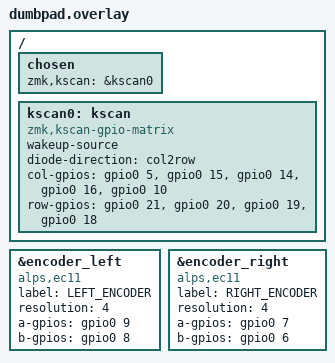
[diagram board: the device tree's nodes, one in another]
/*
 * Copyright (c) 2020 The ZMK Contributors
 *
 * SPDX-License-Identifier: MIT
 */

#include <dt-bindings/zmk/matrix_transform.h>
#include <dt-bindings/zmk/bt.h>
#include "dumbpad.dtsi"

/ {
    chosen {
        zmk,kscan = &kscan0;
    };

    kscan0: kscan {
        compatible = "zmk,kscan-gpio-matrix";
        wakeup-source;
        diode-direction = "col2row";

        col-gpios 
          = <&gpio0 5 (GPIO_ACTIVE_HIGH | GPIO_PULL_DOWN)>,
            <&gpio0 15 (GPIO_ACTIVE_HIGH | GPIO_PULL_DOWN)>,
            <&gpio0 14 (GPIO_ACTIVE_HIGH | GPIO_PULL_DOWN)>,
            <&gpio0 16 (GPIO_ACTIVE_HIGH | GPIO_PULL_DOWN)>,
            <&gpio0 10 (GPIO_ACTIVE_HIGH | GPIO_PULL_DOWN)>;

        row-gpios 
          = <&gpio0 21 (GPIO_ACTIVE_HIGH | GPIO_PULL_DOWN)>,
            <&gpio0 20 (GPIO_ACTIVE_HIGH | GPIO_PULL_DOWN)>,
            <&gpio0 19 (GPIO_ACTIVE_HIGH | GPIO_PULL_DOWN)>,
            <&gpio0 18 (GPIO_ACTIVE_HIGH | GPIO_PULL_DOWN)>;
    };
};

// ✅ Encoder fragments are now outside the root node
&encoder_left {
    compatible = "alps,ec11";
    label = "LEFT_ENCODER";
    resolution = <4>;
    status = "okay";
    a-gpios = <&gpio0 9 (GPIO_ACTIVE_HIGH | GPIO_PULL_UP)>;
    b-gpios = <&gpio0 8 (GPIO_ACTIVE_HIGH | GPIO_PULL_UP)>;
};

&encoder_right {
    compatible = "alps,ec11";
    label = "RIGHT_ENCODER";
    resolution = <4>;
    status = "okay";
    a-gpios = <&gpio0 7 (GPIO_ACTIVE_HIGH | GPIO_PULL_UP)>;
    b-gpios = <&gpio0 6 (GPIO_ACTIVE_HIGH | GPIO_PULL_UP)>;
};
